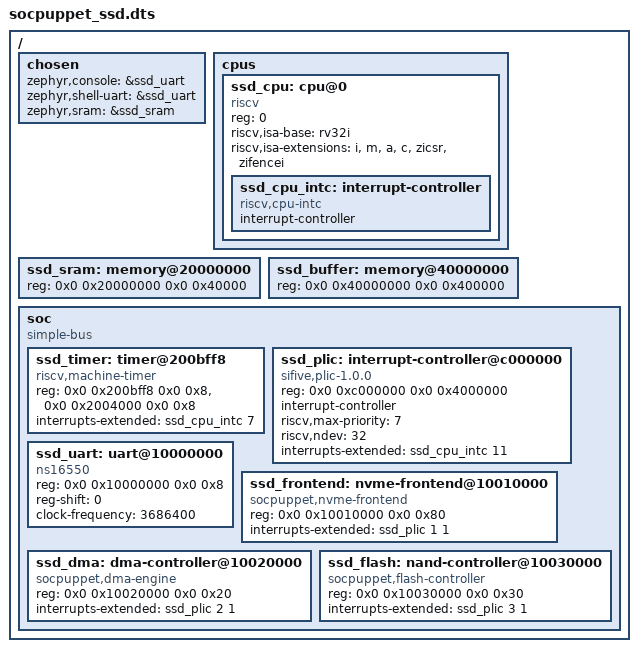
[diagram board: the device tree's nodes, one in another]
/dts-v1/;

/ {
	#address-cells = <2>;
	#size-cells = <2>;

	chosen {
		zephyr,console = &ssd_uart;
		zephyr,shell-uart = &ssd_uart;
		zephyr,sram = &ssd_sram;
	};

	cpus {
		#address-cells = <1>;
		#size-cells = <0>;

		ssd_cpu: cpu@0 {
			device_type = "cpu";
			compatible = "riscv";
			reg = <0>;
			riscv,isa-base = "rv32i";
			riscv,isa-extensions = "i", "m", "a", "c", "zicsr", "zifencei";

			ssd_cpu_intc: interrupt-controller {
				compatible = "riscv,cpu-intc";
				#address-cells = <0>;
				#interrupt-cells = <1>;
				interrupt-controller;
			};
		};
	};

	ssd_sram: memory@20000000 {
		device_type = "memory";
		reg = <0x0 0x20000000 0x0 0x40000>;
	};

	ssd_buffer: memory@40000000 {
		device_type = "memory";
		reg = <0x0 0x40000000 0x0 0x400000>;
	};

	soc {
		compatible = "simple-bus";
		#address-cells = <2>;
		#size-cells = <2>;
		ranges;

		ssd_timer: timer@200bff8 {
			compatible = "riscv,machine-timer";
			reg = <0x0 0x200bff8 0x0 0x8>, <0x0 0x2004000 0x0 0x8>;
			reg-names = "mtime", "mtimecmp";
			interrupts-extended = <&ssd_cpu_intc 7>;
		};

		ssd_plic: interrupt-controller@c000000 {
			compatible = "sifive,plic-1.0.0";
			reg = <0x0 0xc000000 0x0 0x4000000>;
			#address-cells = <0>;
			#interrupt-cells = <2>;
			interrupt-controller;
			riscv,max-priority = <7>;
			riscv,ndev = <32>;
			interrupts-extended = <&ssd_cpu_intc 11>;
		};

		ssd_uart: uart@10000000 {
			compatible = "ns16550";
			reg = <0x0 0x10000000 0x0 0x8>;
			reg-shift = <0>;
			clock-frequency = <3686400>;
		};

		ssd_frontend: nvme-frontend@10010000 {
			compatible = "socpuppet,nvme-frontend";
			reg = <0x0 0x10010000 0x0 0x80>;
			interrupts-extended = <&ssd_plic 1 1>;
		};

		ssd_dma: dma-controller@10020000 {
			compatible = "socpuppet,dma-engine";
			reg = <0x0 0x10020000 0x0 0x20>;
			interrupts-extended = <&ssd_plic 2 1>;
		};

		ssd_flash: nand-controller@10030000 {
			compatible = "socpuppet,flash-controller";
			reg = <0x0 0x10030000 0x0 0x30>;
			interrupts-extended = <&ssd_plic 3 1>;
		};
	};
};
